VERSION ""

NS_ :

BS_:

BU_: XXX

BO_ 884 Doors_Status: 8 XXX
 SG_ 6 : 26|1@0+ (1,0) [0|1] "" XXX
 SG_ Dr : 24|1@0+ (1,0) [0|1] "" XXX
 SG_ Dri : 24|1@0+ (1,0) [0|1] "" XXX
 SG_ Driv : 24|1@0+ (1,0) [0|1] "" XXX
 SG_ Drive : 24|1@0+ (1,0) [0|1] "" XXX
 SG_ Driver : 24|1@0+ (1,0) [0|1] "" XXX
 SG_ DriverF : 24|1@0+ (1,0) [0|1] "" XXX
 SG_ DriverFr : 24|1@0+ (1,0) [0|1] "" XXX
 SG_ DriverFro : 24|1@0+ (1,0) [0|1] "" XXX
 SG_ DriverFron : 24|1@0+ (1,0) [0|1] "" XXX
 SG_ DriverFront : 24|1@0+ (1,0) [0|1] "" XXX
 SG_ DriverFrontD : 24|1@0+ (1,0) [0|1] "" XXX
 SG_ DriverFrontDo : 24|1@0+ (1,0) [0|1] "" XXX
 SG_ DriverFrontDoo : 24|1@0+ (1,0) [0|1] "" XXX
 SG_ DriverFrontDoor : 24|1@0+ (1,0) [0|1] "" XXX
 SG_ DriverFrontDoorS : 24|1@0+ (1,0) [0|1] "" XXX
 SG_ DriverFrontDoorSt : 24|1@0+ (1,0) [0|1] "" XXX
 SG_ DriverFrontDoorSta : 24|1@0+ (1,0) [0|1] "" XXX
 SG_ DriverFrontDoorStat : 24|1@0+ (1,0) [0|1] "" XXX
 SG_ DriverFrontDoorStatu : 24|1@0+ (1,0) [0|1] "" XXX
 SG_ DriverFrontDoorStatus : 24|1@0+ (1,0) [0|1] "" XXX
 SG_ NEW_SIGNAL_1 : 24|1@0+ (1,0) [0|1] "" XXX
 SG_ NEW_SIGNAL_2 : 25|1@0+ (1,0) [0|1] "" XXX
 SG_ NEW_SIGNAL_4 : 27|1@0+ (1,0) [0|1] "" XXX

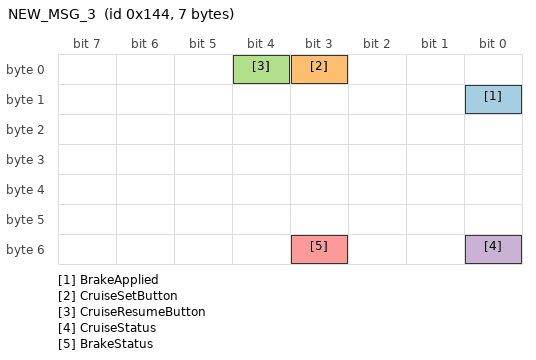
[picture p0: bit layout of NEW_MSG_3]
BO_ 324 NEW_MSG_3: 7 XXX
 SG_ BrakeApplied : 8|1@0+ (1,0) [0|0] "" XXX
 SG_ CruiseSetButton : 3|1@0+ (1,0) [0|0] "" XXX
 SG_ CruiseResumeButton : 4|1@0+ (1,0) [0|0] "" XXX
 SG_ CruiseStatus : 48|1@0+ (1,0) [0|0] "" XXX
 SG_ BrakeStatus : 51|1@0+ (1,0) [0|0] "" XXX

BO_ 320 Throttle: 8 XXX
 SG_ ThrottlePosition : 7|8@0+ (1,0) [0|255] "" XXX

BO_ 209 NEW_MSG_1: 8 XXX
 SG_ BrakePosition : 23|8@0+ (1,0) [0|255] "" XXX

BO_ 2 NEW_MSG_2: 8 XXX
 SG_ SteeringAngle : 7|16@0- (1,0) [-500|500] "degree" XXX

VAL_ 324 BrakeApplied 1 "On" 0 "Off" ;
VAL_ 324 CruiseSetButton 1 "On" 0 "Off" ;
VAL_ 324 CruiseResumeButton 1 "On" 0 "Off" ;
VAL_ 324 CruiseStatus 1 "On" 0 "Off" ;
VAL_ 324 BrakeStatus 1 "On" 0 "Off" ;
